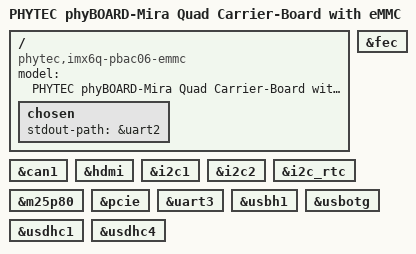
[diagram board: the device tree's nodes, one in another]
// SPDX-License-Identifier: (GPL-2.0+ OR MIT)
/*
 * Copyright (C) 2018 PHYTEC Messtechnik GmbH
 * Author: Christian Hemp <c.hemp@phytec.de>
 */

/dts-v1/;
#include "imx6q.dtsi"
#include "imx6qdl-phytec-phycore-som.dtsi"
#include "imx6qdl-phytec-mira.dtsi"
#include "imx6qdl-phytec-mira-peb-eval-01.dtsi"
#include "imx6qdl-phytec-mira-peb-av-02.dtsi"

/ {
	model = "PHYTEC phyBOARD-Mira Quad Carrier-Board with eMMC";
	compatible = "phytec,imx6q-pbac06-emmc", "phytec,imx6q-pbac06",
		     "phytec,imx6qdl-pcm058", "fsl,imx6q";

	chosen {
		stdout-path = &uart2;
	};
};

&can1 {
	status = "okay";
};

&fec {
	status = "okay";
};

&hdmi {
	status = "okay";
};

&i2c1 {
	status = "okay";
};

&i2c2 {
	status = "okay";
};

&i2c_rtc {
	status = "okay";
};

&m25p80 {
	status = "okay";
};

&pcie {
	status = "okay";
};

&uart3 {
	status = "okay";
};

&usbh1 {
	status = "okay";
};

&usbotg {
	status = "okay";
};

&usdhc1 {
	status = "okay";
};

&usdhc4 {
	status = "okay";
};
